# STM32MP21_CM33 register map
File version: 0.4
CPU: CM33 r0p1, little endian, MPU, FPU, vendor SysTick, 8 interrupt priority bits
Registers are 32-bit, read-write, reset 0x0 unless marked. A register's access mark holds for its fields unless they carry their own. Offsets are from the block's base; [hi:lo] are bit positions; {n}, {i} and the like mark numbered series; 'fields as' and 'values as' point back to an identical list.

## ETH1 (part 1 of 2) — ETH address block description
Base 0x482C0000
Same registers: ETH2 0x482D0000, ETH1_S 0x582C0000, ETH2_S 0x582D0000
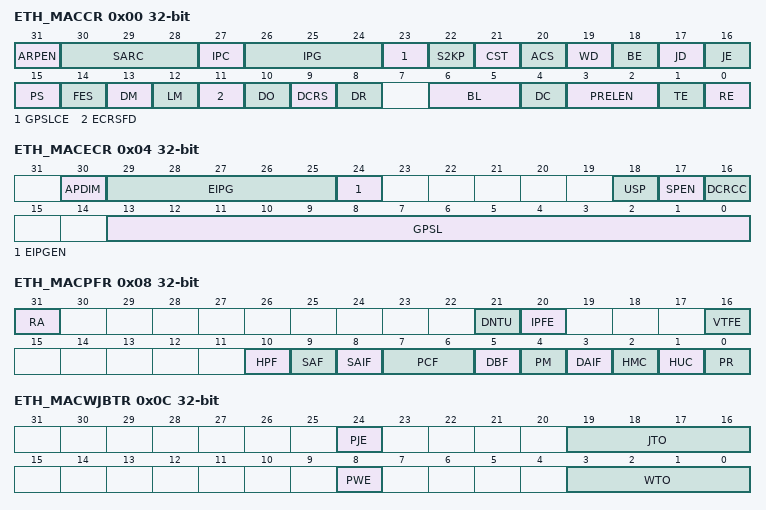
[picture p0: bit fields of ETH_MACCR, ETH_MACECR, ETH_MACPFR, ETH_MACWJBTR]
0x00 ETH_MACCR — Operating mode configuration register
  [31] ARPEN — ARP Offload Enable
  [30:28] SARC — Source Address Insertion or Replacement Control
    2=the MAC inserts the content of the MAC Address 0 registers (MAC Address 0 high register (ETH_MACA0HR) and MAC Address x low register (ETH_MACAxLR)) in the SA field of all transmitted packets; 3=the MAC replaces the content of the MAC Address 0 registers (MAC Address 0 high register (ETH_MACA0HR) and MAC Address x low register (ETH_MACAxLR)) in the SA field of all transmitted packets; 6=the MAC inserts the content of the MAC Address 1 registers (MAC Address x high register (ETH_MACAxHR) and MAC Address x low register (ETH_MACAxLR)) in the SA field of all transmitted packets; 7=the MAC replaces the content of the MAC Address 1 registers (MAC Address x high register (ETH_MACAxHR) and MAC Address x low register (ETH_MACAxLR)) in the SA field of all transmitted packets
  [27] IPC — Checksum Offload
  [26:24] IPG — Inter-Packet Gap
    0=96 bit times; 1=88 bit times; 2=80 bit times; 7=40 bit times
  [23] GPSLCE — Giant Packet Size Limit Control Enable
  [22] S2KP — IEEE 802.
  [21] CST — CRC stripping for Type packets
  [20] ACS — Automatic Pad or CRC Stripping
  [19] WD — Watchdog Disable
  [18] BE — Packet Burst Enable
  [17] JD — Jabber Disable
  [16] JE — Jumbo Packet Enable
  [15] PS — Port Select
    0=For 1000 Mbps operations; 1=For 10 or 100 Mbps operations
  [14] FES — MAC Speed
    0=10 Mbps; 1=100 Mbps
  [13] DM — Duplex Mode
  [12] LM — Loopback Mode
  [11] ECRSFD — Enable Carrier Sense Before Transmission in Full-duplex mode
  [10] DO — Disable Receive Own
  [9] DCRS — Disable Carrier Sense During Transmission
  [8] DR — Disable Retry
  [6:5] BL — Back-Off Limit
    0=k= min (n, 10); 1=k = min (n, 8); 2=k = min (n, 4); 3=k = min (n, 1)
  [4] DC — Deferral Check
  [3:2] PRELEN — Preamble Length for Transmit packets
    0=7 bytes of preamble; 1=5 bytes of preamble; 2=3 bytes of preamble
  [1] TE — Transmitter Enable
  [0] RE — Receiver Enable
0x04 ETH_MACECR — Extended operating mode configuration register
  [30] APDIM — ARP Packet Drop if IP Address Mismatch
  [29:25] EIPG — Extended Inter-Packet Gap
  [24] EIPGEN — Extended Inter-Packet Gap Enable
  [18] USP — Unicast Slow Protocol Packet Detect
  [17] SPEN — Slow Protocol Detection Enable
  [16] DCRCC — Disable CRC Checking for Received Packets
  [13:0] GPSL — Giant Packet Size Limit
0x08 ETH_MACPFR — Packet filtering control register
  [31] RA — Receive All
  [21] DNTU — Drop Non-TCP/UDP over IP Packets
  [20] IPFE — Layer 3 and Layer 4 Filter Enable
  [16] VTFE — VLAN Tag Filter Enable
  [10] HPF — Hash or Perfect Filter
  [9] SAF — Source Address Filter Enable
  [8] SAIF — SA Inverse Filtering
  [7:6] PCF — Pass Control Packets
    0=The MAC filters all control packets from reaching the application; 1=The MAC forwards all control packets except Pause packets to the application even if they fail the Address filter; 2=The MAC forwards all control packets to the application even if they fail the Address filter; 3=The MAC forwards the control packets that pass the Address filter
  [5] DBF — Disable Broadcast Packets
  [4] PM — Pass All Multicast
  [3] DAIF — DA Inverse Filtering
  [2] HMC — Hash Multicast
  [1] HUC — Hash Unicast
  [0] PR — Promiscuous Mode
0x0C ETH_MACWJBTR — Watchdog and jabber timeout register
  [24] PJE — Programmable Jabber Enable
  [19:16] JTO — Jabber Timeout
    {v}={v+2} Kbytes (v=0..3); 12=14 Kbytes; 13=15 Kbytes; 14=16383 Bytes
  [8] PWE — Programmable Watchdog Enable
  [3:0] WTO — Watchdog Timeout
    values as JTO
0x10 ETH_MACHT0R — Hash Table 0 register
  [31:0] HT31T0 — MAC Hash Table First 32 Bits
0x14 ETH_MACHT1R — Hash Table 1 register
  [31:0] HT63T32 — MAC Hash Table Second 32 Bits
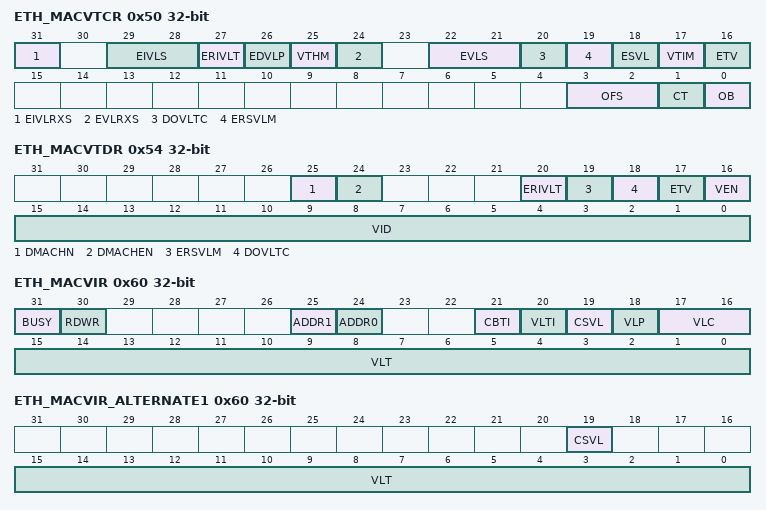
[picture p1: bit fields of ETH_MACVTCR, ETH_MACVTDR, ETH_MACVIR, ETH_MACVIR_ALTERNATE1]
0x50 ETH_MACVTCR — VLAN tag Control register
  [31] EIVLRXS — Enable Inner VLAN Tag in Rx Status
  [29:28] EIVLS — Enable Inner VLAN Tag Stripping on Receive
    0=Do not strip; 1=Strip if VLAN filter passes; 2=Strip if VLAN filter fails; 3=Always strip
  [27] ERIVLT — Enable Inner VLAN Tag
  [26] EDVLP — Enable Double VLAN Processing
  [25] VTHM — VLAN Tag Hash Table Match Enable
  [24] EVLRXS — Enable VLAN Tag in Rx status
  [22:21] EVLS — Enable VLAN Tag Stripping on Receive
    values as EIVLS
  [20] DOVLTC — Disable VLAN Type Check
  [19] ERSVLM — Enable Receive S-VLAN Match
  [18] ESVL — Enable S-VLAN
  [17] VTIM — VLAN Tag Inverse Match Enable
  [16] ETV — Enable 12-Bit VLAN Tag Comparison
  [3:2] OFS — Offset
    {v}=ETH_MACVTDR holds MAC VLAN Tag Filter{v} content (v=0..3)
  [1] CT — Command Type
  [0] OB — Operation Busy
0x54 ETH_MACVTDR — VLAN tag data register
  [25] DMACHN — DMA Channel Number
  [24] DMACHEN — DMA Channel Number Enable
  [20] ERIVLT — Enable Inner VLAN Tag Comparison
  [19] ERSVLM — Enable S-VLAN Match for received Frames
  [18] DOVLTC — Disable VLAN Type Comparison
  [17] ETV — 12-bit or 16-bit VLAN comparison
    0=16-bit VLAN; 1=12-bit VLAN
  [16] VEN — VLAN Tag Enable
  [15:0] VID — VLAN Tag ID
0x58 ETH_MACVHTR — VLAN Hash table register
  [15:0] VLHT — VLAN Hash Table
0x60 ETH_MACVIR — VLAN inclusion register
  [31] BUSY ro
  [30] RDWR — Read write control
  [25] ADDR1 — Address
    0=VLAN tag for insertion in the Transmit packets from Tx Queue 0; 1=VLAN tag for insertion in the Transmit packets from Tx Queue 1
  [24] ADDR0 — Address
    values as ADDR1
  [21] CBTI — Channel based tag insertion
  [20] VLTI — VLAN Tag Input
  [19] CSVL — C-VLAN or S-VLAN
    0=C-LAN; 1=S-LAN
  [18] VLP — VLAN Priority Control
  [17:16] VLC — VLAN Tag Control in Transmit Packets
    0=No VLAN tag deletion, insertion, or replacement; 1=VLAN tag deletion; 2=VLAN tag insertion; 3=VLAN tag replacement
  [15:0] VLT — VLAN Tag for Transmit Packets
0x60 ETH_MACVIR_ALTERNATE1 (alternate view of ETH_MACVIR) — VLAN inclusion register
  [19] CSVL — C-VLAN or S-VLAN
    0=C-LAN; 1=S-LAN
  [15:0] VLT — VLAN Tag for Transmit Packets
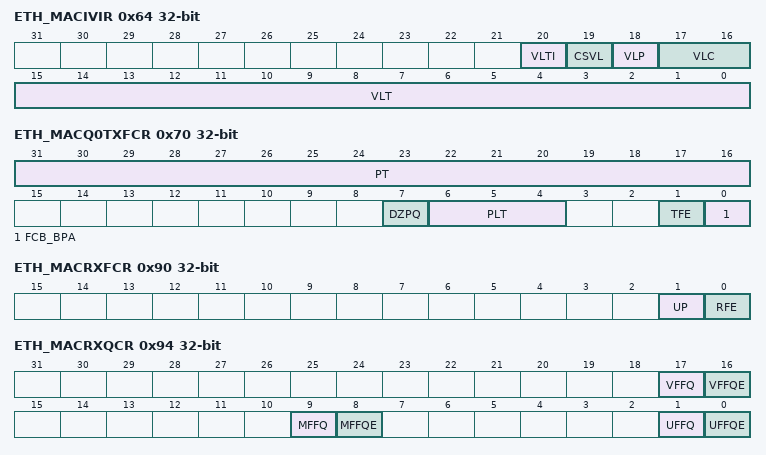
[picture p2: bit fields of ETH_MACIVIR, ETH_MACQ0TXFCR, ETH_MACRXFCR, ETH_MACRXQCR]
0x64 ETH_MACIVIR — Inner VLAN inclusion register
  [20] VLTI — VLAN Tag Input
  [19] CSVL — C-VLAN or S-VLAN
    0=C-LAN; 1=S-LAN
  [18] VLP — VLAN Priority Control
  [17:16] VLC — VLAN Tag Control in Transmit Packets
    values as ETH_MACVIR.VLC
  [15:0] VLT — VLAN Tag for Transmit Packets
0x70 ETH_MACQ0TXFCR — Tx Queue 0 flow control register
  [31:16] PT — Pause Time
  [7] DZPQ — Disable Zero-Quanta Pause
  [6:4] PLT — Pause Low Threshold
    0=Pause Time minus 4 Slot Times (PT -4 slot times); 1=Pause Time minus 28 Slot Times (PT -28 slot times); 2=Pause Time minus 36 Slot Times (PT -36 slot times); 3=Pause Time minus 144 Slot Times (PT -144 slot times); 4=Pause Time minus 256 Slot Times (PT -256 slot times); 5=Pause Time minus 512 Slot Times (PT -512 slot times)
  [1] TFE — Transmit Flow Control Enable
  [0] FCB_BPA — Flow Control Busy or Backpressure Activate
0x90 ETH_MACRXFCR — Rx flow control register
  [1] UP — Unicast Pause Packet Detect
  [0] RFE — Receive Flow Control Enable
0x94 ETH_MACRXQCR — Rx Queue control register
  [17] VFFQ — VLAN Tag Filter Fail Packets Queue
    0=Queue 0; 1=Queue 1
  [16] VFFQE — VLAN Tag Filter Fail Packets Queuing Enable
    0=Disabled; 1=Enabled
  [9] MFFQ — Multicast Address Filter Fail Packets Queue.
    0=Queue 0; 1=Queue 1
  [8] MFFQE — Multicast Address Filter Fail Packets Queuing Enable.
  [1] UFFQ — Unicast Address Filter Fail Packets Queue.
    0=Queue 0; 1=Queue 1
  [0] UFFQE — Unicast Address Filter Fail Packets Queuing Enable.
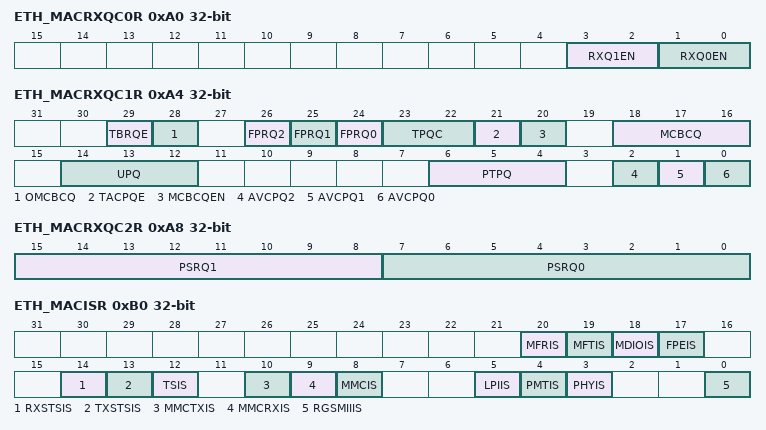
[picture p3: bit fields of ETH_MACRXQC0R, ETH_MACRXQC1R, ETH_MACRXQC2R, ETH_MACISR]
0xA0 ETH_MACRXQC0R — Rx queue control 0 register
  [3:2] RXQ1EN — Receive Queue 1 Enable
    0=Not enabled; 1=Queue 1 enabled for AV; 2=Queue 1 enabled for Generic traffic
  [1:0] RXQ0EN — Receive Queue 0 Enable
    0=Not enabled; 1=Queue 0 enabled for AV; 2=Queue 0 enabled for Generic traffic
0xA4 ETH_MACRXQC1R — Rx queue control 1 register
  [29] TBRQE — Type Field Based Rx Queuing Enable
  [28] OMCBCQ — Overriding MC-BC queue priority select
    1=Priority of MCBCQ is reduced and the received packet is first routed to PTPQ, AVCPQ, depending on packet type; 0=Received Multicast/Broadcast packet is routed to MCBCQ
  [26] FPRQ2 — Frame Preemption Residue Queue
    1=Rx queue 1
  [25] FPRQ1 — Frame Preemption Residue Queue
    1=Rx queue 1
  [24] FPRQ0 — Frame Preemption Residue Queue
    1=Rx queue 1
  [23:22] TPQC — Tagged PTP over Ethernet Packets Queuing Control
    0=VLAN tagged PTPoE packets are routed as generic VLAN tagged packet (based on PSRQ for only non-AV enabled Rx queues); 1=VLAN tagged PTPoE packets are routed to Rx Queue specified by PTPQ field (this Rx Queue can be enabled for AV or non-AV traffic); 2=VLAN tagged PTPoE packets are routed to only AV enabled Rx queues based on PSRQ
  [21] TACPQE — Tagged AV Control Packets Queuing Enable
  [20] MCBCQEN — Multicast and Broadcast Queue Enable
  [18:16] MCBCQ — Multicast and Broadcast Queue
    0=Rx queue 0; 1=Rx queue 1
  [14:12] UPQ — Untagged Packet Queue
    0=Rx queue 0; 1=Rx queue 1
  [6:4] PTPQ — PTP Packets Queue
    0=Rx queue 0; 1=Rx queue 1
  [2] AVCPQ2 — AV Untagged Control Packets Queue
    0=Receive Queue 0; 1=Receive Queue 1
  [1] AVCPQ1 — AV Untagged Control Packets Queue
    0=Receive Queue 0; 1=Receive Queue 1
  [0] AVCPQ0 — AV Untagged Control Packets Queue
    0=Receive Queue 0; 1=Receive Queue 1
0xA8 ETH_MACRXQC2R — Rx queue control 2 register
  [15:8] PSRQ1 — Priorities Selected in the Receive Queue 1
  [7:0] PSRQ0 — Priorities Selected in the Receive Queue 0
0xB0 ETH_MACISR — Interrupt status register
  [20] MFRIS ro — MMC FPE Receive Interrupt Status
  [19] MFTIS ro — MMC FPE Transmit Interrupt Status
  [18] MDIOIS — MDIO Interrupt Status
  [17] FPEIS ro — Frame Preemption Interrupt Status
  [14] RXSTSIS — Receive Status Interrupt
  [13] TXSTSIS — Transmit Status Interrupt
  [12] TSIS — Timestamp Interrupt Status
  [10] MMCTXIS ro — MMC Transmit Interrupt Status
  [9] MMCRXIS ro — MMC Receive Interrupt Status
  [8] MMCIS ro — MMC Interrupt Status
  [5] LPIIS ro — LPI Interrupt Status
  [4] PMTIS ro — PMT Interrupt Status
  [3] PHYIS ro — PHY Interrupt
  [0] RGSMIIIS ro — RGMII Interrupt Status
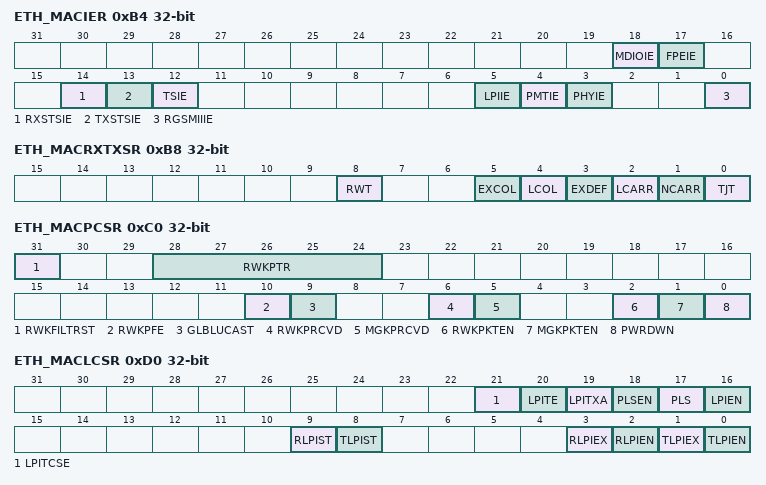
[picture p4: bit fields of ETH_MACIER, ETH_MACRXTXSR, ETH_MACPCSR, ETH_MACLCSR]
0xB4 ETH_MACIER — Interrupt enable register
  [18] MDIOIE — MDIO Interrupt Enable
  [17] FPEIE — Frame Preemption Interrupt Enable
  [14] RXSTSIE — Receive Status Interrupt Enable
  [13] TXSTSIE — Transmit Status Interrupt Enable
  [12] TSIE — Timestamp Interrupt Enable
  [5] LPIIE — LPI Interrupt Enable
  [4] PMTIE — PMT Interrupt Enable
  [3] PHYIE — PHY Interrupt Enable
  [0] RGSMIIIE — RGMII Interrupt Enable
0xB8 ETH_MACRXTXSR — Rx Tx status register
  [8] RWT — Receive Watchdog Timeout
  [5] EXCOL — Excessive Collisions
  [4] LCOL — Late Collision
  [3] EXDEF — Excessive Deferral
  [2] LCARR — Loss of Carrier
  [1] NCARR — No Carrier
  [0] TJT — Transmit Jabber Timeout
0xC0 ETH_MACPCSR — PMT control status register
  [31] RWKFILTRST — Remote Wake-up Packet Filter Register Pointer Reset
  [28:24] RWKPTR ro — Remote wake-up FIFO Pointer
  [10] RWKPFE — Remote wake-up Packet Forwarding Enable
  [9] GLBLUCAST — Global Unicast
  [6] RWKPRCVD ro — Remote wake-up Packet Received
  [5] MGKPRCVD — Magic Packet Received
  [2] RWKPKTEN — Remote wake-up Packet Enable
  [1] MGKPKTEN — Magic Packet Enable
  [0] PWRDWN — Power Down
0xC4 ETH_MACRWKPFR — Remote wake-up packet filter register
  [31:0] MACRWKPFR — Remote wake-up packet filter
0xD0 ETH_MACLCSR — LPI control and status register
  [21] LPITCSE — LPI Tx Clock Stop Enable
  [20] LPITE — LPI Timer Enable
  [19] LPITXA — LPI Tx Automate
  [18] PLSEN — PHY Link Status Enable
  [17] PLS — PHY Link Status
  [16] LPIEN — LPI Enable
  [9] RLPIST ro — Receive LPI State
  [8] TLPIST ro — Transmit LPI State
  [3] RLPIEX ro — Receive LPI Exit
  [2] RLPIEN ro — Receive LPI Entry
  [1] TLPIEX ro — Transmit LPI Exit
  [0] TLPIEN ro — Transmit LPI Entry
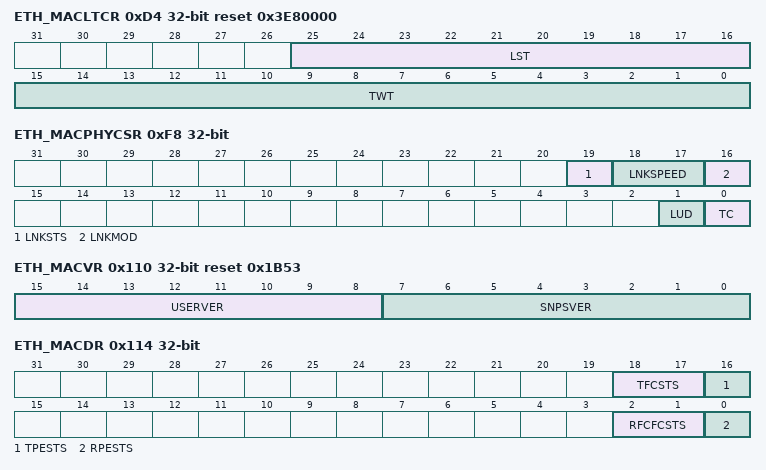
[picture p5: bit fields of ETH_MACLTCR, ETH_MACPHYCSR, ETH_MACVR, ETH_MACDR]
0xD4 ETH_MACLTCR reset 0x3E80000 — LPI timers control register
  [25:16] LST — LPI LS Timer
  [15:0] TWT — LPI TW Timer
0xD8 ETH_MACLETR — LPI entry timer register
  [19:0] LPIET — LPI Entry Timer
0xDC ETH_MAC1USTCR reset 0x63 — One-microsecond-tick counter register
  [11:0] TIC_1US_CNTR — 1us tick Counter
0xF8 ETH_MACPHYCSR — PHYIF control status register
  [19] LNKSTS ro — Link Status
    0=Link down; 1=Link up
  [18:17] LNKSPEED ro — Link Speed
    0=2; 1=25 MHz; 2=125 MHz
  [16] LNKMOD ro — Link Mode
    0=Half-duplex mode; 1=Full-duplex mode
  [1] LUD — Link Up or Down
    0=Link Down; 1=Link Up
  [0] TC — Transmit Configuration in RGMII
0x110 ETH_MACVR ro reset 0x1B53 — Version register
  [15:8] USERVER — ST-defined version
  [7:0] SNPSVER — IP version
0x114 ETH_MACDR ro — Debug register
  [18:17] TFCSTS — MAC Transmit Packet Controller Status
    0=Idle state; 1=Waiting for one of the following:; 2=Generating and transmitting a Pause control packet (in Full-duplex mode); 3=Transferring input packet for transmission
  [16] TPESTS — MAC GMII or MII Transmit Protocol Engine Status
  [2:1] RFCFCSTS — MAC Receive Packet Controller FIFO Status
  [0] RPESTS — MAC GMII or MII Receive Protocol Engine Status
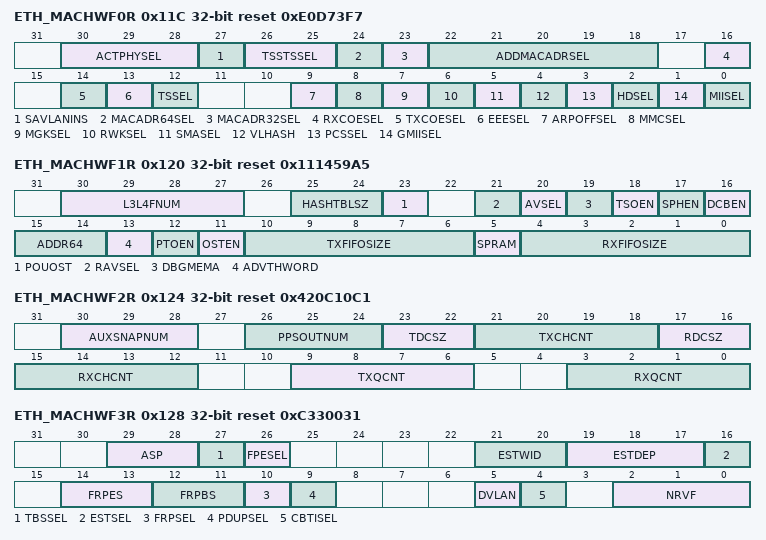
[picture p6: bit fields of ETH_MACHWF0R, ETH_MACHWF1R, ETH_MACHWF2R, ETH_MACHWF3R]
0x11C ETH_MACHWF0R ro reset 0xE0D73F7 — HW feature 0 register
  [30:28] ACTPHYSEL — Active PHY Selected
    0=GMII or MII; 1=RGMII; 2=SGMII; 3=TBI; 4=RMII; 5=RTBI; 6=SMII
  [27] SAVLANINS — Source Address or VLAN Insertion Enable
  [26:25] TSSTSSEL — Timestamp System Time Source
    1=Internal; 2=External; 3=Both
  [24] MACADR64SEL — MAC Addresses 64-127 Selected
  [23] MACADR32SEL — MAC Addresses 32-63 Selected
  [22:18] ADDMACADRSEL — MAC Addresses 1-31 Selected
  [16] RXCOESEL — Receive Checksum Offload Enabled
  [14] TXCOESEL — Transmit Checksum Offload Enabled
  [13] EEESEL — Energy Efficient Ethernet Enabled
  [12] TSSEL — IEEE 1588-2008 Timestamp Enabled
  [9] ARPOFFSEL — ARP Offload Enabled
  [8] MMCSEL — RMON Module Enable
  [7] MGKSEL — PMT Magic Packet Enable
  [6] RWKSEL — PMT Remote Wake-up Packet Enable
  [5] SMASEL — SMA (MDIO) Interface
  [4] VLHASH — VLAN Hash Filter Selected
  [3] PCSSEL — PCS Registers (TBI, SGMII, or RTBI PHY interface)
  [2] HDSEL — Half-duplex Support
  [1] GMIISEL — 1000 Mbps Support
  [0] MIISEL — 10 or 100 Mbps Support
0x120 ETH_MACHWF1R ro reset 0x111459A5 — HW feature 1 register
  [30:27] L3L4FNUM — Total number of L3 or L4 Filters
    0=No L3 or L4 Filter; 1=1 L3 or L4 Filter; 2=2 L3 or L4 Filters; 8=8 L3 or L4
  [25:24] HASHTBLSZ — Hash Table Size
    0=No Hash table; 1=64; 2=128; 3=256
  [23] POUOST — One Step for PTP over UDP/IP Feature Enable
  [21] RAVSEL — Rx Side Only AV Feature Enable
  [20] AVSEL — AV Feature Enable
  [19] DBGMEMA — DMA Debug Registers Enable
  [18] TSOEN — TCP Segmentation Offload Enable
  [17] SPHEN — Split Header Feature Enable
  [16] DCBEN — DCB Feature Enable
  [15:14] ADDR64 — Address width
    0=32 bits
  [13] ADVTHWORD — IEEE 1588 High Word Register Enable
  [12] PTOEN — PTP Offload Enable
  [11] OSTEN — One-Step Timestamping Enable
  [10:6] TXFIFOSIZE — MTL Transmit FIFO Size
    0=128 bytes; 1=256 bytes; 2=512 bytes; 3=1,024 bytes; 4=2,048 bytes; 5=4,096 bytes; 6=8,192 bytes; 7=16,384 bytes; 8=32 Kbytes; 9=64 Kbytes; 10=128 Kbytes
  [5] SPRAM — Single Port RAM Enable
  [4:0] RXFIFOSIZE — MTL Receive FIFO Size
    0=128 bytes; 1=256 bytes; 2=512 bytes; 3=1,024 bytes; 4=2,048 bytes; 5=4,096 bytes; 6=8,192 bytes; 7=16,384 bytes; 8=32 Kbytes; 9=64 Kbytes; 10=128 Kbytes; 11=256 Kbytes
0x124 ETH_MACHWF2R ro reset 0x420C10C1 — HW feature 2 register
  [30:28] AUXSNAPNUM — Number of Auxiliary Snapshot Inputs
    0=No auxiliary input; 1=1 auxiliary input; 2=2 auxiliary inputs; 3=3 auxiliary inputs; 4=4 auxiliary inputs
  [26:24] PPSOUTNUM — Number of PPS Outputs
    0=No PPS output; 1=1 PPS output; 2=2 PPS outputs; 3=3 PPS outputs; 4=4 PPS outputs
  [23:22] TDCSZ — Tx DMA Descriptor Cache Size in terms of 16-byte descriptors
    0=Cache not configured; 1=Four 16-byte descriptors; 2=Eight 16-byte descriptors; 3=Sixteen 16-byte descriptors
  [21:18] TXCHCNT — Number of DMA Transmit Channels
    0=1 DMA Tx Channel; 1=2 DMA Tx Channels; 7=8 DMA Tx
  [17:16] RDCSZ — Rx DMA Descriptor Cache Size in terms of 16-byte descriptors
    values as TDCSZ
  [15:12] RXCHCNT — Number of DMA Receive Channels
    0=1 DMA Rx Channel; 1=2 DMA Rx Channels; 7=8 DMA Rx
  [9:6] TXQCNT — Number of MTL Transmit Queues
    0=1 MTL Tx queue; 1=2 MTL Tx queues; 7=8 MTL Tx
  [3:0] RXQCNT — Number of MTL Receive Queues
    0=1 MTL Rx queue; 1=2 MTL Rx queues; 7=8 MTL Rx
0x128 ETH_MACHWF3R ro reset 0xC330031 — HW feature 3 register
  [29:28] ASP — Automotive Safety Package
    0=None; 1=ECC only; 2=AS_NPPE; 3=AS_PPE
  [27] TBSSEL — Time-based scheduling Enable
  [26] FPESEL — Frame Preemption Enable
  [21:20] ESTWID — Width of the Time Interval field in the Gate Control List
    0=No width; 1=16; 2=20; 3=24
  [19:17] ESTDEP — Depth of the Gate Control List
    0=No depth; 1=64; 2=128; 3=256; 4=512; 5=1024
  [16] ESTSEL — Enhancements to Scheduled Traffic Enable
  [14:13] FRPES — Flexible Receive Parser Table Entries size
    0=64 entries; 1=128 entries; 2=256 entries
  [12:11] FRPBS — Flexible Receive Parser Buffer size
    0=64 bytes; 1=128 bytes; 2=256 bytes
  [10] FRPSEL — Flexible Receive Parser Selected
  [9] PDUPSEL — Broadcast/Multicast Packet Duplication
  [5] DVLAN — Double VLAN processing enable
  [4] CBTISEL — Queue/Channel based VLAN tag insertion on Tx enable
  [2:0] NRVF — Number of Extended VLAN Tag Filters Enabled
    0=No Extended Rx VLAN Filters; 1=4 Extended Rx VLAN Filters; 2=8 Extended Rx VLAN Filters; 3=16 Extended Rx VLAN Filters; 4=24 Extended Rx VLAN Filters; 5=32 Extended Rx VLAN Filters
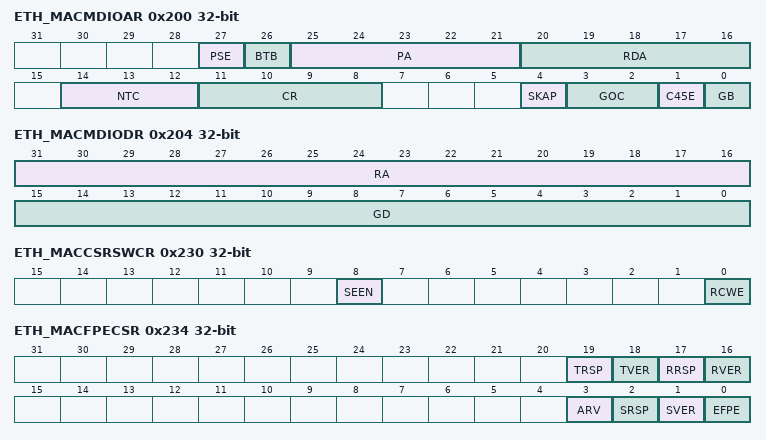
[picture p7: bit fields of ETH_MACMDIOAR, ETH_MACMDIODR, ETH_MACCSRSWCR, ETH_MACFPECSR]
0x200 ETH_MACMDIOAR — MDIO address register
  [27] PSE — Preamble Suppression Enable
  [26] BTB — Back to Back transactions
  [25:21] PA — Physical Layer Address
  [20:16] RDA — Register/Device Address
  [14:12] NTC — Number of Training Clocks
  [11:8] CR — CSR Clock Range
    0=MDC clock = eth_hclk/42; 1=MDC clock = eth_hclk /62; 2=MDC clock = eth_hclk / 16; 3=MDC clock = eth_hclk / 26; 4=MDC clock = eth_hclk/102; 5=MDC clock = eth_hclk / 124; 6=MDC clock = eth_hclk/204; 7=MDC clock = eth_hclk/324; 8=eth_hclk / 4; 9=eth_hclk / 6; 10=eth_hclk / 8; 11=eth_hclk / 10; 12=eth_hclk / 12; 13=eth_hclk / 14; 14=eth_hclk / 16; 15=eth_hclk / 18
  [4] SKAP — Skip Address Packet
  [3:2] GOC — GMII Operation Command
    1=Write; 2=Post Read Increment Address for Clause 45 PHY; 3=Read
  [1] C45E — Clause 45 PHY Enable
  [0] GB — GMII Busy
0x204 ETH_MACMDIODR — MDIO data register
  [31:16] RA — Register Address
  [15:0] GD — GMII Data
0x210 ETH_MACARPAR — ARP address register
  [31:0] ARPPA — ARP Protocol Address
0x230 ETH_MACCSRSWCR — CSR software control register
  [8] SEEN — Slave Error Response Enable
  [0] RCWE — Register Clear on Write 1 Enable
0x234 ETH_MACFPECSR — FPE control and status register
  [19] TRSP — Transmitted Respond Frame
  [18] TVER — Transmitted Verify Frame
  [17] RRSP — Received Respond Frame
  [16] RVER — Received Verify Frame
  [3] ARV — Autogenerate Respond mPacket on receiving Verify mPacket
  [2] SRSP — Send Respond mPacket
  [1] SVER — Send Verify mPacket
  [0] EFPE — Enable Tx Frame Preemption
0x240 ETH_MACPRSTIMR — MAC presentation time register
  [31:0] MPTN — MAC 1722 Presentation Time in ns
0x244 ETH_MACPRSTIMUR — MAC presentation time update register
  [31:0] MPTU — MAC 1722 Presentation Time Update
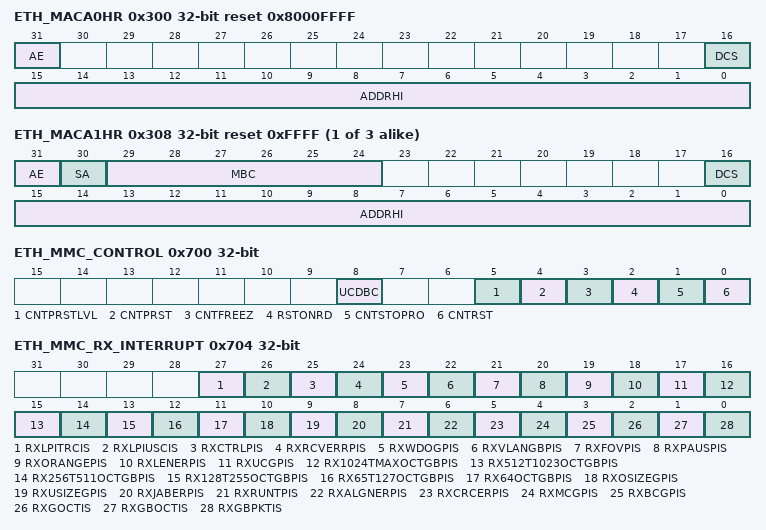
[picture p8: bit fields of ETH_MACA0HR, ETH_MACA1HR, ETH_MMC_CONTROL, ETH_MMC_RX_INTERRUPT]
0x300 ETH_MACA0HR reset 0x8000FFFF — MAC Address 0 high register
  [31] AE ro — Address Enable
  [16] DCS — DMA Channel Select
    0=DMA Rx channel 0; 1=DMA Rx channel 1
  [15:0] ADDRHI — MAC Address0[47:32]
{0x304+8i} ETH_MACA{i}LR reset 0xFFFFFFFF (i=0..3) — MAC Address {i} low register
  [31:0] ADDRLO — MAC Address x [31:0]
{0x300+8i} ETH_MACA{i}HR reset 0xFFFF (i=1..3) — MAC Address {i} high register
  [31] AE — Address Enable
  [30] SA — Source Address
    0=DA; 1=SA
  [29:24] MBC — Mask Byte Control
  [16] DCS — DMA Channel Select
    0=DMA Rx channel 0; 1=DMA Rx channel 1
  [15:0] ADDRHI — MAC Address1 [47:32]
0x700 ETH_MMC_CONTROL — MMC control register
  [8] UCDBC — Update MMC Counters for Dropped Broadcast Packets
  [5] CNTPRSTLVL — Full-Half Preset
  [4] CNTPRST — Counters Preset
  [3] CNTFREEZ — MMC Counter Freeze
  [2] RSTONRD — Reset on Read
  [1] CNTSTOPRO — Counter Stop Rollover
  [0] CNTRST — Counters Reset
0x704 ETH_MMC_RX_INTERRUPT — MMC Rx interrupt register
  [27] RXLPITRCIS — MMC Receive LPI transition counter interrupt status
  [26] RXLPIUSCIS — MMC Receive LPI microsecond counter interrupt status
  [25] RXCTRLPIS — MMC Receive Control Packet Counter Interrupt Status
  [24] RXRCVERRPIS — MMC Receive Error Packet Counter Interrupt Status
  [23] RXWDOGPIS — MMC Receive Watchdog Error Packet Counter Interrupt Status
  [22] RXVLANGBPIS — MMC Receive VLAN Good Bad Packet Counter Interrupt Status
  [21] RXFOVPIS — MMC Receive FIFO Overflow Packet Counter Interrupt Status
  [20] RXPAUSPIS — MMC Receive Pause Packet Counter Interrupt Status
  [19] RXORANGEPIS — MMC Receive Out Of Range Error Packet Counter Interrupt Status
  [18] RXLENERPIS — MMC Receive Length Error Packet Counter Interrupt Status
  [17] RXUCGPIS — MMC Receive Unicast Good Packet Counter Interrupt Status
  [16] RX1024TMAXOCTGBPIS — MMC Receive 1024 to Maximum Octet Good Bad Packet Counter Interrupt Status
  [15] RX512T1023OCTGBPIS — MMC Receive 512 to 1023 Octet Good Bad Packet Counter Interrupt Status
  [14] RX256T511OCTGBPIS — MMC Receive 256 to 511 Octet Good Bad Packet Counter Interrupt Status
  [13] RX128T255OCTGBPIS — MMC Receive 128 to 255 Octet Good Bad Packet Counter Interrupt Status
  [12] RX65T127OCTGBPIS — MMC Receive 65 to 127 Octet Good Bad Packet Counter Interrupt Status
  [11] RX64OCTGBPIS — MMC Receive 64 Octet Good Bad Packet Counter Interrupt Status
  [10] RXOSIZEGPIS — MMC Receive Oversize Good Packet Counter Interrupt Status
  [9] RXUSIZEGPIS — MMC Receive Undersize Good Packet Counter Interrupt Status
  [8] RXJABERPIS — MMC Receive Jabber Error Packet Counter Interrupt Status
  [7] RXRUNTPIS — MMC Receive Runt Packet Counter Interrupt Status
  [6] RXALGNERPIS — MMC Receive Alignment Error Packet Counter Interrupt Status
  [5] RXCRCERPIS — MMC Receive CRC Error Packet Counter Interrupt Status
  [4] RXMCGPIS — MMC Receive Multicast Good Packet Counter Interrupt Status
  [3] RXBCGPIS — MMC Receive Broadcast Good Packet Counter Interrupt Status
  [2] RXGOCTIS — MMC Receive Good Octet Counter Interrupt Status
  [1] RXGBOCTIS — MMC Receive Good Bad Octet Counter Interrupt Status
  [0] RXGBPKTIS — MMC Receive Good Bad Packet Counter Interrupt Status
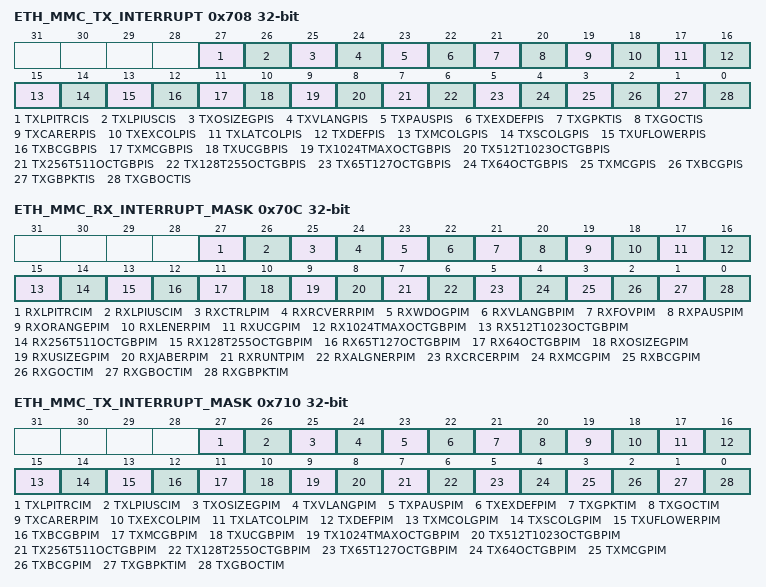
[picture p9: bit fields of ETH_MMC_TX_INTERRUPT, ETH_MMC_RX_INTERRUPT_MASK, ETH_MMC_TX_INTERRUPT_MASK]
0x708 ETH_MMC_TX_INTERRUPT — MMC Tx interrupt register
  [27] TXLPITRCIS — MMC Transmit LPI transition counter interrupt status
  [26] TXLPIUSCIS — MMC Transmit LPI microsecond counter interrupt status
  [25] TXOSIZEGPIS — MMC Transmit Oversize Good Packet Counter Interrupt Status
  [24] TXVLANGPIS — MMC Transmit VLAN Good Packet Counter Interrupt Status
  [23] TXPAUSPIS — MMC Transmit Pause Packet Counter Interrupt Status
  [22] TXEXDEFPIS — MMC Transmit Excessive Deferral Packet Counter Interrupt Status
  [21] TXGPKTIS — MMC Transmit Good Packet Counter Interrupt Status
  [20] TXGOCTIS — MMC Transmit Good Octet Counter Interrupt Status
  [19] TXCARERPIS — MMC Transmit Carrier Error Packet Counter Interrupt Status
  [18] TXEXCOLPIS — MMC Transmit Excessive Collision Packet Counter Interrupt Status
  [17] TXLATCOLPIS — MMC Transmit Late Collision Packet Counter Interrupt Status
  [16] TXDEFPIS — MMC Transmit Deferred Packet Counter Interrupt Status
  [15] TXMCOLGPIS — MMC Transmit Multiple Collision Good Packet Counter Interrupt Status
  [14] TXSCOLGPIS — MMC Transmit Single Collision Good Packet Counter Interrupt Status
  [13] TXUFLOWERPIS — MMC Transmit Underflow Error Packet Counter Interrupt Status
  [12] TXBCGBPIS — MMC Transmit Broadcast Good Bad Packet Counter Interrupt Status
  [11] TXMCGBPIS — MMC Transmit Multicast Good Bad Packet Counter Interrupt Status
  [10] TXUCGBPIS — MMC Transmit Unicast Good Bad Packet Counter Interrupt Status
  [9] TX1024TMAXOCTGBPIS — MMC Transmit 1024 to Maximum Octet Good Bad Packet Counter Interrupt Status
  [8] TX512T1023OCTGBPIS — MMC Transmit 512 to 1023 Octet Good Bad Packet Counter
  [7] TX256T511OCTGBPIS — MMC Transmit 256 to 511 Octet Good Bad Packet Counter
  [6] TX128T255OCTGBPIS — MMC Transmit 128 to 255 Octet Good Bad Packet Counter
  [5] TX65T127OCTGBPIS — MMC Transmit 65 to 127 Octet Good Bad Packet Counter
  [4] TX64OCTGBPIS — MMC Transmit 64 Octet Good Bad Packet Counter Interrupt Status
  [3] TXMCGPIS — MMC Transmit Multicast Good Packet Counter Interrupt Status
  [2] TXBCGPIS — MMC Transmit Broadcast Good Packet Counter Interrupt Status
  [1] TXGBPKTIS — MMC Transmit Good Bad Packet Counter Interrupt Status
  [0] TXGBOCTIS — MMC Transmit Good Bad Octet Counter Interrupt Status
0x70C ETH_MMC_RX_INTERRUPT_MASK — MMC Rx interrupt mask register
  [27] RXLPITRCIM — MMC Receive LPI transition counter interrupt Mask
  [26] RXLPIUSCIM — MMC Receive LPI microsecond counter interrupt Mask
  [25] RXCTRLPIM — MMC Receive Control Packet Counter Interrupt Mask
  [24] RXRCVERRPIM — MMC Receive Error Packet Counter Interrupt Mask
  [23] RXWDOGPIM — MMC Receive Watchdog Error Packet Counter Interrupt Mask
  [22] RXVLANGBPIM — MMC Receive VLAN Good Bad Packet Counter Interrupt Mask
  [21] RXFOVPIM — MMC Receive FIFO Overflow Packet Counter Interrupt Mask
  [20] RXPAUSPIM — MMC Receive Pause Packet Counter Interrupt Mask
  [19] RXORANGEPIM — MMC Receive Out Of Range Error Packet Counter Interrupt Mask
  [18] RXLENERPIM — MMC Receive Length Error Packet Counter Interrupt Mask
  [17] RXUCGPIM — MMC Receive Unicast Good Packet Counter Interrupt Mask
  [16] RX1024TMAXOCTGBPIM — MMC Receive 1024 to Maximum Octet Good Bad Packet Counter Interrupt Mask
  [15] RX512T1023OCTGBPIM — MMC Receive 512 to 1023 Octet Good Bad Packet Counter Interrupt Mask
  [14] RX256T511OCTGBPIM — MMC Receive 256 to 511 Octet Good Bad Packet Counter Interrupt Mask
  [13] RX128T255OCTGBPIM — MMC Receive 128 to 255 Octet Good Bad Packet Counter Interrupt Mask
  [12] RX65T127OCTGBPIM — MMC Receive 65 to 127 Octet Good Bad Packet Counter Interrupt Mask
  [11] RX64OCTGBPIM — MMC Receive 64 Octet Good Bad Packet Counter Interrupt Mask
  [10] RXOSIZEGPIM — MMC Receive Oversize Good Packet Counter Interrupt Mask
  [9] RXUSIZEGPIM — MMC Receive Undersize Good Packet Counter Interrupt Mask
  [8] RXJABERPIM — MMC Receive Jabber Error Packet Counter Interrupt Mask
  [7] RXRUNTPIM — MMC Receive Runt Packet Counter Interrupt Mask
  [6] RXALGNERPIM — MMC Receive Alignment Error Packet Counter Interrupt Mask
  [5] RXCRCERPIM — MMC Receive CRC Error Packet Counter Interrupt Mask
  [4] RXMCGPIM — MMC Receive Multicast Good Packet Counter Interrupt Mask
  [3] RXBCGPIM — MMC Receive Broadcast Good Packet Counter Interrupt Mask
  [2] RXGOCTIM — MMC Receive Good Octet Counter Interrupt Mask
  [1] RXGBOCTIM — MMC Receive Good Bad Octet Counter Interrupt Mask
  [0] RXGBPKTIM — MMC Receive Good Bad Packet Counter Interrupt Mask
0x710 ETH_MMC_TX_INTERRUPT_MASK — MMC Tx interrupt mask register
  [27] TXLPITRCIM — MMC Transmit LPI transition counter interrupt Mask
  [26] TXLPIUSCIM — MMC Transmit LPI microsecond counter interrupt Mask
  [25] TXOSIZEGPIM — MMC Transmit Oversize Good Packet Counter Interrupt Mask
  [24] TXVLANGPIM — MMC Transmit VLAN Good Packet Counter Interrupt Mask
  [23] TXPAUSPIM — MMC Transmit Pause Packet Counter Interrupt Mask
  [22] TXEXDEFPIM — MMC Transmit Excessive Deferral Packet Counter Interrupt Mask
  [21] TXGPKTIM — MMC Transmit Good Packet Counter Interrupt Mask
  [20] TXGOCTIM — MMC Transmit Good Octet Counter Interrupt Mask
  [19] TXCARERPIM — MMC Transmit Carrier Error Packet Counter Interrupt Mask
  [18] TXEXCOLPIM — MMC Transmit Excessive Collision Packet Counter Interrupt Mask
  [17] TXLATCOLPIM — MMC Transmit Late Collision Packet Counter Interrupt Mask
  [16] TXDEFPIM — MMC Transmit Deferred Packet Counter Interrupt Mask
  [15] TXMCOLGPIM — MMC Transmit Multiple Collision Good Packet Counter Interrupt Mask
  [14] TXSCOLGPIM — MMC Transmit Single Collision Good Packet Counter Interrupt Mask
  [13] TXUFLOWERPIM — MMC Transmit Underflow Error Packet Counter Interrupt Mask
  [12] TXBCGBPIM — MMC Transmit Broadcast Good Bad Packet Counter Interrupt Mask
  [11] TXMCGBPIM — MMC Transmit Multicast Good Bad Packet Counter Interrupt Mask
  [10] TXUCGBPIM — MMC Transmit Unicast Good Bad Packet Counter Interrupt Mask
  [9] TX1024TMAXOCTGBPIM — MMC Transmit 1024 to Maximum Octet Good Bad Packet Counter Interrupt Mask
  [8] TX512T1023OCTGBPIM — MMC Transmit 512 to 1023 Octet Good Bad Packet Counter
  [7] TX256T511OCTGBPIM — MMC Transmit 256 to 511 Octet Good Bad Packet Counter
  [6] TX128T255OCTGBPIM — MMC Transmit 128 to 255 Octet Good Bad Packet Counter
  [5] TX65T127OCTGBPIM — MMC Transmit 65 to 127 Octet Good Bad Packet Counter
  [4] TX64OCTGBPIM — MMC Transmit 64 Octet Good Bad Packet Counter Interrupt Mask
  [3] TXMCGPIM — MMC Transmit Multicast Good Packet Counter Interrupt Mask
  [2] TXBCGPIM — MMC Transmit Broadcast Good Packet Counter Interrupt Mask
  [1] TXGBPKTIM — MMC Transmit Good Bad Packet Counter Interrupt Mask
  [0] TXGBOCTIM — MMC Transmit Good Bad Octet Counter Interrupt Mask
0x714 ETH_TX_OCTET_COUNT_GOOD_BAD ro — Tx octet count good bad register
  [31:0] TXOCTGB — Tx Octet Count Good Bad
0x718 ETH_TX_PACKET_COUNT_GOOD_BAD ro — Tx packet count good bad register
  [31:0] TXPKTGB — Tx Packet Count Good Bad
0x71C ETH_TX_BROADCAST_PACKETS_GOOD ro — Tx broadcast packets good register
  [31:0] TXBCASTG — Tx Broadcast Packets Good
0x720 ETH_TX_MULTICAST_PACKETS_GOOD ro — Tx multicast packets good register
  [31:0] TXMCASTG — Tx multicast Packets Good
0x724 ETH_TX_64OCTETS_PACKETS_GOOD_BAD ro — Tx 64 octets packets good bad register
  [31:0] TX64OCTGB — Tx 64 octets Packets Good Bad
0x728 ETH_TX_64TO127OCTETS_PACKETS_GOOD_BAD ro — Tx 65 to 127 octets packets good bad register
  [31:0] TX65_127OCTGB — Tx 65 to 127 octets Packets Good Bad
0x72C ETH_TX_128TO255OCTETS_PACKETS_GOOD_BAD ro — Tx 128 to 255 octets packets good bad register
  [31:0] TX128_255OCTGB — Tx 128 to 255 octets Packets Good Bad
0x730 ETH_TX_256TO511OCTETS_PACKETS_GOOD_BAD ro — Tx 256 to 511 octets packets good bad register
  [31:0] TX256_511OCTGB — Tx 256 to 511 octets Packets Good Bad
0x734 ETH_TX_512TO1023OCTETS_PACKETS_GOOD_BAD ro — Tx 512 to 1023 octets packets good bad register
  [31:0] TX512_1023OCTGB — Tx 512 to 1023 octets Packets Good Bad
0x738 ETH_TX_1024TOMAXOCTETS_PACKETS_GOOD_BAD ro — Tx 1024 to max octets packets good bad register
  [31:0] TX1024_MAXOCTGB — Tx 1024 to Max octets Packets Good Bad
0x73C ETH_TX_UNICAST_PACKETS_GOOD_BAD ro — Tx unicast packets good bad register
  [31:0] TXUCASTGB — Tx Unicast Packets Good Bad
0x740 ETH_TX_MULTICAST_PACKETS_GOOD_BAD ro — Tx multicast packets good bad register
  [31:0] TXMCASTGB — Tx Multicast Packets Good Bad
0x744 ETH_TX_BROADCAST_PACKETS_GOOD_BAD ro — Tx broadcast packets good bad register
  [31:0] TXBCASTGB — Tx Broadcast Packets Good Bad
0x748 ETH_TX_UNDERFLOW_ERROR_PACKETS ro — Tx underflow error packets register
  [31:0] TXUNDRFLW — Tx Underflow Error Packets
0x74C ETH_TX_SINGLE_COLLISION_GOOD_PACKETS ro — Tx single collision good packets register
  [31:0] TXSNGLCOLG — Tx Single Collision Good Packets
0x750 ETH_TX_MULTIPLE_COLLISION_GOOD_PACKETS ro — Tx multiple collision good packets register
  [31:0] TXMULTCOLG — Tx Multiple Collision Good Packets
0x754 ETH_TX_DEFERRED_PACKETS ro — Tx deferred packets register
  [31:0] TXDEFRD — Tx Deferred Packets
0x758 ETH_TX_LATE_COLLISION_PACKETS ro — Tx late collision packets register
  [31:0] TXLATECOL — Tx Late Collision Packets
0x75C ETH_TX_EXCESSIVE_COLLISION_PACKETS ro — Tx excessive collision packets register
  [31:0] TXEXSCOL — Tx Excessive Collision Packets
0x760 ETH_TX_CARRIER_ERROR_PACKETS ro — Tx carrier error packets register
  [31:0] TXCARR — Tx Carrier Error Packets
0x764 ETH_TX_OCTET_COUNT_GOOD ro — Tx octet count good register
  [31:0] TXOCTG — Tx Octet Count Good
0x768 ETH_TX_PACKET_COUNT_GOOD ro — Tx packet count good register
  [31:0] TXPKTG — Tx Packet Count Good
0x76C ETH_TX_EXCESSIVE_DEFERRAL_ERROR ro — Tx excessive deferral error register
  [31:0] TXEXSDEF — Tx Excessive Deferral Error
0x770 ETH_TX_PAUSE_PACKETS ro — Tx pause packets register
  [31:0] TXPAUSE — Tx Pause Packets
0x774 ETH_TX_VLAN_PACKETS_GOOD ro — Tx VLAN packets good register
  [31:0] TXVLANG — Tx VLAN Packets Good
0x778 ETH_TX_OSIZE_PACKETS_GOOD ro — Tx OSsize packets good register
  [31:0] TXOSIZG — Tx OSize Packets Good
0x780 ETH_RX_PACKETS_COUNT_GOOD_BAD ro — Rx packets count good bad register
  [31:0] RXPKTGB — Rx Packets Count Good Bad
0x784 ETH_RX_OCTET_COUNT_GOOD_BAD ro — Rx octet count good bad register
  [31:0] RXOCTGB — Rx Octet Count Good Bad
0x788 ETH_RX_OCTET_COUNT_GOOD ro — Rx octet count good register
  [31:0] RXOCTG — Rx Octet Count Good
0x78C ETH_RX_BROADCAST_PACKETS_GOOD ro — Rx broadcast packets good register
  [31:0] RXBCASTG — Rx Broadcast Packets Good
0x790 ETH_RX_MULTICAST_PACKETS_GOOD ro — Rx multicast packets good register
  [31:0] RXMCASTG — Rx Multicast Packets Good
0x794 ETH_RX_CRC_ERROR_PACKETS ro — Rx CRC error packets register
  [31:0] RXCRCERR — Rx CRC Error Packets
0x798 ETH_RX_ALIGNMENT_ERROR_PACKETS ro — Rx alignment error packets register
  [31:0] RXALGNERR — Rx Alignment Error Packets
0x79C ETH_RX_RUNT_ERROR_PACKETS ro — Rx runt error packets register
  [31:0] RXRUNTERR — Rx Runt Error Packets
0x7A0 ETH_RX_JABBER_ERROR_PACKETS ro — Rx jabber error packets register
  [31:0] RXJABERR — Rx Jabber Error Packets
0x7A4 ETH_RX_UNDERSIZE_PACKETS_GOOD ro — Rx undersize packets good register
  [31:0] RXUNDERSZG — Rx Undersize Packets Good
0x7A8 ETH_RX_OVERSIZE_PACKETS_GOOD ro — Rx oversize packets good register
  [31:0] RXOVERSZG — Rx Oversize Packets Good
0x7AC ETH_RX_64OCTETS_PACKETS_GOOD_BAD ro — Rx 64 octets packets good bad register
  [31:0] RX64OCTGB — Rx 64 Octets Packets Good Bad
0x7B0 ETH_RX_65TO127OCTETS_PACKETS_GOOD_BAD ro — Rx 65 to 127 octets packets good bad register
  [31:0] TX65_127OCTGB — Rx 65-127 Octets Packets Good Bad
0x7B4 ETH_RX_128TO255OCTETS_PACKETS_GOOD_BAD ro — Rx 128 to 255 octets packets good bad register
  [31:0] RX128_255OCTGB — Rx 128-255 Octets Packets Good Bad
